# R7FA6T2BD register map
Vendor: Renesas Electronics Corporation; Series: RA6; File version: 1.30.01
CPU: CM33 r0p4, little endian, MPU, FPU, VTOR, 4 interrupt priority bits, 96 interrupts
Registers are 32-bit, read-write, reset 0x0 unless marked. A register's access mark holds for its fields unless they carry their own. Offsets are from the block's base; [hi:lo] are bit positions; 'fields as' and 'values as' point back to an identical list.

## CAC — Clock Frequency Accuracy Measurement Circuit
Base 0x40083600
0x00 CACR0 8-bit — CAC Control Register 0
  [0] CFME — Clock Frequency Measurement Enable
    0=Disable; 1=Enable
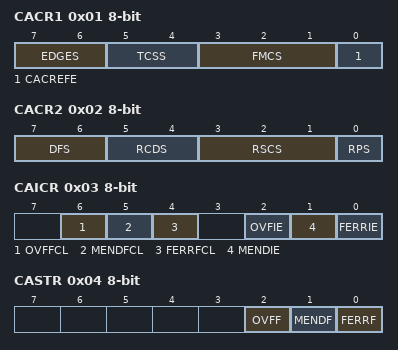
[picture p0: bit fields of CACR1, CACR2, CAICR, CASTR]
0x01 CACR1 8-bit — CAC Control Register 1
  [7:6] EDGES — Valid Edge Select
    0=Rising edge; 1=Falling edge; 2=Both rising and falling edges; 3=Setting prohibited
  [5:4] TCSS — Timer Count Clock Source Select
    0=No division; 1=x 1/4 clock; 2=x 1/8 clock; 3=x 1/32 clock
  [3:1] FMCS — Measurement Target Clock Select
    0=Main clock oscillator; 1=Setting prohibited; 2=HOCO clock; 3=MOCO clock; 4=LOCO clock; 5=Peripheral module clock B (PCLKB); 6=IWDT-dedicated clock; 7=Setting prohibited
  [0] CACREFE — CACREF Pin Input Enable
    0=Disable; 1=Enable
0x02 CACR2 8-bit — CAC Control Register 2
  [7:6] DFS — Digital Filter Select
    0=Disable digital filtering; 1=Use sampling clock for the digital filter as the frequency measuring clock; 2=Use sampling clock for the digital filter as the frequency measuring clock divided by 4; 3=Use sampling clock for the digital filter as the frequency measuring clock divided by 16
  [5:4] RCDS — Measurement Reference Clock Frequency Division Ratio Select
    0=x 1/32 clock; 1=x 1/128 clock; 2=x 1/1024 clock; 3=x 1/8192 clock
  [3:1] RSCS — Measurement Reference Clock Select
    values as CACR1.FMCS
  [0] RPS — Reference Signal Select
    0=CACREF pin input; 1=Internal clock (internally generated signal)
0x03 CAICR 8-bit — CAC Interrupt Control Register
  [6] OVFFCL wo — OVFF Clear
    0=No effect; 1=The CASTR.OVFF flag is cleared
  [5] MENDFCL wo — MENDF Clear
    0=No effect; 1=The CASTR.MENDF flag is cleared
  [4] FERRFCL wo — FERRF Clear
    0=No effect; 1=The CASTR.FERRF flag is cleared
  [2] OVFIE — Overflow Interrupt Request Enable
    0=Disable; 1=Enable
  [1] MENDIE — Measurement End Interrupt Request Enable
    0=Disable; 1=Enable
  [0] FERRIE — Frequency Error Interrupt Request Enable
    0=Disable; 1=Enable
0x04 CASTR 8-bit ro — CAC Status Register
  [2] OVFF — Overflow Flag
    0=Counter has not overflowed; 1=Counter overflowed
  [1] MENDF — Measurement End Flag
    0=Measurement is in progress; 1=Measurement ended
  [0] FERRF — Frequency Error Flag
    0=Clock frequency is within the allowable range; 1=Clock frequency has deviated beyond the allowable range (frequency error)
0x06 CAULVR 16-bit — CAC Upper-Limit Value Setting Register
0x08 CALLVR 16-bit — CAC Lower-Limit Value Setting Register
0x0A CACNTBR 16-bit ro — CAC Counter Buffer Register

## MSTP — Module Stop Control
Base 0x40084000
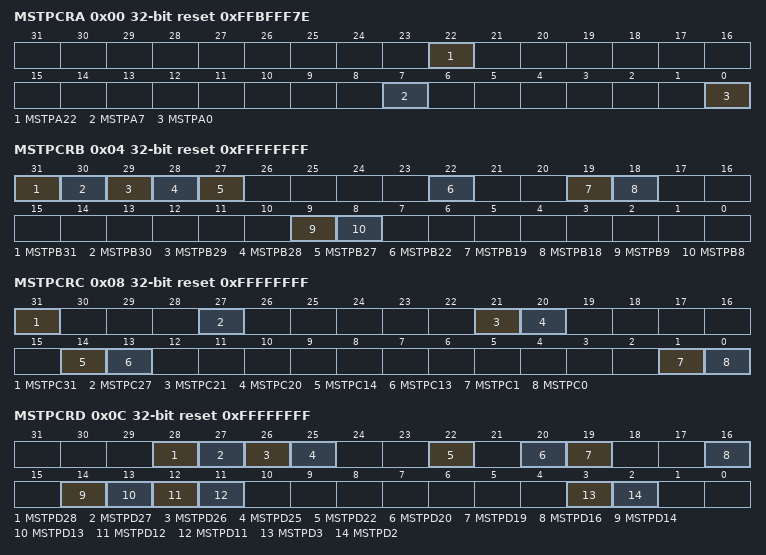
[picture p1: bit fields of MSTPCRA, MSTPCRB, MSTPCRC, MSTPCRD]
0x00 MSTPCRA reset 0xFFBFFF7E — Module Stop Control Register A
  [all] fields
    0=Cancel the module-stop state; 1=Enter the module-stop state
  [22] MSTPA22 — DMA Controller/Data Transfer Controller Module Stop
  [7] MSTPA7 — Standby SRAM Module Stop
  [0] MSTPA0 — SRAM0 Module Stop
0x04 MSTPCRB reset 0xFFFFFFFF — Module Stop Control Register B
  [all] fields
    values as the fields of MSTPCRA
  [31] MSTPB31 — Serial Communication Interface 0 Module Stop
  [30] MSTPB30 — Serial Communication Interface 1 Module Stop
  [29] MSTPB29 — Serial Communication Interface 2 Module Stop
  [28] MSTPB28 — Serial Communication Interface 3 Module Stop
  [27] MSTPB27 — Serial Communication Interface 4 Module Stop
  [22] MSTPB22 — Serial Communication Interface 9 Module Stop
  [19] MSTPB19 — Serial Peripheral Interface 0 Module Stop
  [18] MSTPB18 — Serial Peripheral Interface 1 Module Stop
  [9] MSTPB9 — I2C Bus Interface 0 Module Stop
  [8] MSTPB8 — I2C Bus Interface 1 Module Stop
0x08 MSTPCRC reset 0xFFFFFFFF — Module Stop Control Register C
  [all] fields
    values as the fields of MSTPCRA
  [31] MSTPC31 — Secure Cryptographic Engine Module Stop
  [27] MSTPC27 — CANFD Module Stop
  [21] MSTPC21 — IIR Filter Accelerator Module Stop
  [20] MSTPC20 — Trigonometric Function Unit Module Stop
  [14] MSTPC14 — Event Link Controller Module Stop
  [13] MSTPC13 — Data Operation Circuit Module Stop
  [1] MSTPC1 — Cyclic Redundancy Check Module Stop
  [0] MSTPC0 — Clock Frequency Accuracy Measurement Circuit Module Stop
0x0C MSTPCRD reset 0xFFFFFFFF — Module Stop Control Register D
  [all] fields
    values as the fields of MSTPCRA
  [28] MSTPD28 — High-Speed Analog Comparator 0 Module Stop
  [27] MSTPD27 — High-Speed Analog Comparator 1 Module Stop
  [26] MSTPD26 — High-Speed Analog Comparator 2 Module Stop
  [25] MSTPD25 — High-Speed Analog Comparator 3 Module Stop
  [22] MSTPD22 — Temperature Sensor Module Stop
  [20] MSTPD20 — 12-bit D/A Converter 0 Module Stop
  [19] MSTPD19 — 12-bit D/A Converter 1 Module Stop
  [16] MSTPD16 — A/D Converter Module Stop
  [14] MSTPD14 — Port Output Enable for GPT Group A Module Stop
  [13] MSTPD13 — Port Output Enable for GPT Group B Module Stop
  [12] MSTPD12 — Port Output Enable for GPT Group C Module Stop
  [11] MSTPD11 — Port Output Enable for GPT Group D Module Stop
  [3] MSTPD3 — Low Power Asynchronous General Purpose Timer 0 Module Stop
  [2] MSTPD2 — Low Power Asynchronous General Purpose Timer 1 Module Stop
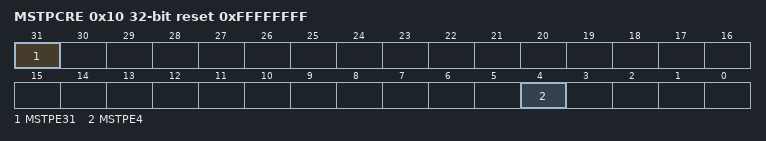
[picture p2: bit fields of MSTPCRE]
0x10 MSTPCRE reset 0xFFFFFFFF — Module Stop Control Register E
  [31] MSTPE31 — General PWM Timer and PWM Delay Generation Circuit Module Stop
    values as the fields of MSTPCRA
  [4] MSTPE4 — Key Interrupt Function Module Stop
    values as the fields of MSTPCRA
